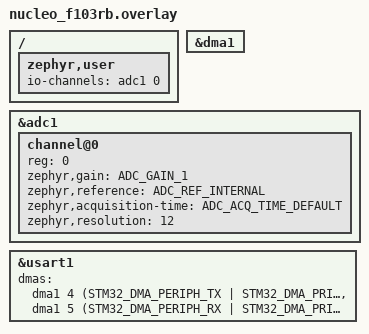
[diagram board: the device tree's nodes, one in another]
/*
 * Copyright (c) 2022 Kumar Gala <galak@kernel.org>
 *
 * SPDX-License-Identifier: Apache-2.0
 */

tst_dma0: &dma1 {};

/ {
	zephyr,user {
		io-channels = <&adc1 0>;
	};
};

&adc1 {
	#address-cells = <1>;
	#size-cells = <0>;
	channel@0 {
		reg = <0>;
		zephyr,gain = "ADC_GAIN_1";
		zephyr,reference = "ADC_REF_INTERNAL";
		zephyr,acquisition-time = <ADC_ACQ_TIME_DEFAULT>;
		zephyr,resolution = <12>;
	};
};

dut: &usart1 {
	dmas = <&dma1 4 (STM32_DMA_PERIPH_TX | STM32_DMA_PRIORITY_HIGH)>,
	       <&dma1 5 (STM32_DMA_PERIPH_RX | STM32_DMA_PRIORITY_HIGH)>;
	dma-names = "tx", "rx";
};

&dma1 {
	status = "okay";
};
